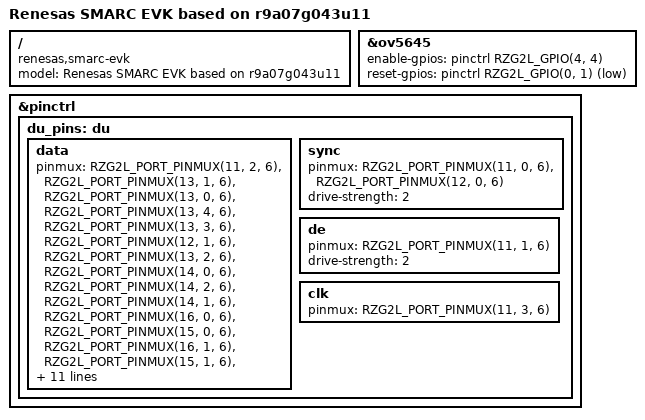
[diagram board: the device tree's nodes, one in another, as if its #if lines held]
// SPDX-License-Identifier: (GPL-2.0-only OR BSD-2-Clause)
/*
 * Device Tree Source for the RZ/G2UL Type-1 SMARC EVK board
 *
 * Copyright (C) 2022 Renesas Electronics Corp.
 */

/dts-v1/;

/*
 * DIP-Switch SW1 setting
 * 1 : High; 0: Low
 * SW1-2 : SW_SD0_DEV_SEL	(0: uSD; 1: eMMC)
 * SW1-3 : SW_ET0_EN_N		(0: ETHER0; 1: CAN0, CAN1, SSI1, RSPI1)
 * Please change below macros according to SW1 setting on the SoM
 */
#define SW_SW0_DEV_SEL	1
#define SW_ET0_EN_N	1

/*
 * To enable MTU3a PWM on PMOD0,
 *  - Set DIP-Switch SW1-3 to On position.
 *  - Set PMOD_MTU3 macro to 1.
 */
#define PMOD_MTU3	0

#if (PMOD_MTU3 && !SW_ET0_EN_N)
#error "Cannot set as both PMOD_MTU3 and !SW_ET0_EN_N are mutually exclusive"
#endif

/* Please set this macro to 1 for enabling SCI0 on PMOD1 */
#define PMOD_SCI0_EN	0

#include "r9a07g043u.dtsi"
#include "rzg2ul-smarc-som.dtsi"
#include "rzg2ul-smarc.dtsi"

#define OV5645_PARENT_I2C i2c0
#include "rz-smarc-cru-csi-ov5645.dtsi"

#define ADV7513_PARENT_I2C i2c1
#include "rz-smarc-du-adv7513.dtsi"

/ {
	model = "Renesas SMARC EVK based on r9a07g043u11";
	compatible = "renesas,smarc-evk", "renesas,r9a07g043u11", "renesas,r9a07g043";
};

&ov5645 {
	enable-gpios = <&pinctrl RZG2L_GPIO(4, 4) GPIO_ACTIVE_HIGH>;
	reset-gpios = <&pinctrl RZG2L_GPIO(0, 1) GPIO_ACTIVE_LOW>;
};

&pinctrl {
	du_pins: du {
		data {
			pinmux = <RZG2L_PORT_PINMUX(11, 2, 6)>,
				 <RZG2L_PORT_PINMUX(13, 1, 6)>,
				 <RZG2L_PORT_PINMUX(13, 0, 6)>,
				 <RZG2L_PORT_PINMUX(13, 4, 6)>,
				 <RZG2L_PORT_PINMUX(13, 3, 6)>,
				 <RZG2L_PORT_PINMUX(12, 1, 6)>,
				 <RZG2L_PORT_PINMUX(13, 2, 6)>,
				 <RZG2L_PORT_PINMUX(14, 0, 6)>,
				 <RZG2L_PORT_PINMUX(14, 2, 6)>,
				 <RZG2L_PORT_PINMUX(14, 1, 6)>,
				 <RZG2L_PORT_PINMUX(16, 0, 6)>,
				 <RZG2L_PORT_PINMUX(15, 0, 6)>,
				 <RZG2L_PORT_PINMUX(16, 1, 6)>,
				 <RZG2L_PORT_PINMUX(15, 1, 6)>,
				 <RZG2L_PORT_PINMUX(15, 3, 6)>,
				 <RZG2L_PORT_PINMUX(18, 0, 6)>,
				 <RZG2L_PORT_PINMUX(15, 2, 6)>,
				 <RZG2L_PORT_PINMUX(17, 0, 6)>,
				 <RZG2L_PORT_PINMUX(17, 2, 6)>,
				 <RZG2L_PORT_PINMUX(17, 1, 6)>,
				 <RZG2L_PORT_PINMUX(18, 1, 6)>,
				 <RZG2L_PORT_PINMUX(18, 2, 6)>,
				 <RZG2L_PORT_PINMUX(17, 3, 6)>,
				 <RZG2L_PORT_PINMUX(18, 3, 6)>;
			drive-strength = <2>;
		};

		sync {
			pinmux = <RZG2L_PORT_PINMUX(11, 0, 6)>, /* HSYNC */
				 <RZG2L_PORT_PINMUX(12, 0, 6)>; /* VSYNC */
			drive-strength = <2>;
		};

		de {
			pinmux = <RZG2L_PORT_PINMUX(11, 1, 6)>; /* DE */
			drive-strength = <2>;
		};

		clk {
			pinmux = <RZG2L_PORT_PINMUX(11, 3, 6)>; /* CLK */
		};
	};
};
